VERSION ""

NS_ :

BS_:

BU_: SME EDME REME KLE GWS RDME

BO_ 3221225472 VECTOR__INDEPENDENT_SIG_MSG: 0 Vector__XXX
 SG_ FC_Contactor_Test : 0|1@0+ (1,0) [0|1] "" Vector__XXX
 SG_ Displayed_SOC : 0|8@1+ (0.5,0) [0|100] "%" Vector__XXX
 SG_ CV_Setpoint : 0|12@1+ (0.1,0) [0|409.4] "Volts" Vector__XXX
 SG_ New_Signal_79 : 16|8@1+ (1,0) [0|0] "" Vector__XXX
 SG_ Frame0_1D6 : 0|8@1+ (1,0) [0|0] "" Vector__XXX
 SG_ Frame1_1D6 : 8|8@1+ (1,0) [0|0] "" Vector__XXX
 SG_ DataHighVol : 0|8@1+ (1,0) [0|0] "" Vector__XXX
 SG_ I_Available : 24|16@1+ (0.1,0) [-500|500] "Amps" Vector__XXX
 SG_ V_Avail : 8|16@1+ (0.1,0) [0|1000] "Volts" Vector__XXX
 SG_ Thresh_V : 40|16@1+ (0.1,0) [0|600] "V" Vector__XXX
 SG_ Weld_Det_En : 0|2@1+ (1,0) [0|4] "" Vector__XXX
 SG_ internal_charger_status : 2|4@1+ (1,0) [0|16] "" Vector__XXX
 SG_ CCS_Protocol : 56|8@1+ (1,0) [0|255] "" Vector__XXX
 SG_ Iso_Status : 6|2@1+ (1,0) [0|3] "" Vector__XXX
 SG_ MinV_Avail : 0|16@1+ (0.1,0) [0|1000] "Volts" Vector__XXX
 SG_ Min_I_Avail : 16|12@1+ (0.1,0) [0|410] "A" Vector__XXX
 SG_ Energy_Transmitted : 56|8@1+ (0.25,0) [0|63] "kWh" Vector__XXX
 SG_ Power_Limit : 52|2@1+ (1,0) [0|2] "" Vector__XXX
 SG_ Battery_Compatability : 38|2@1+ (1,0) [0|4] "" Vector__XXX
 SG_ CHG_Volts : 0|16@1+ (0.1,0) [0|1] "Volts" Vector__XXX
 SG_ CHG_Amps : 16|16@1+ (0.1,0) [-500|500] "Amps" Vector__XXX
 SG_ I_Limit : 44|2@1+ (1,0) [0|1] "" Vector__XXX
 SG_ V_Limit : 46|2@1+ (1,0) [0|3] "" Vector__XXX
 SG_ Batt_Malf : 40|2@1+ (1,0) [0|3] "" Vector__XXX
 SG_ Charge_Status : 32|2@1+ (1,0) [0|3] "" Vector__XXX
 SG_ CCS_Malf : 34|2@1+ (1,0) [0|3] "" Vector__XXX
 SG_ DC_Chg_Stop : 42|2@1+ (1,0) [0|3] "" Vector__XXX
 SG_ Pilot_Current : 0|8@1+ (1,0) [0|63] "Amps" Vector__XXX
 SG_ Cable_Current : 8|8@1+ (1,0) [0|63] "Amps" Vector__XXX
 SG_ FC_Voltage : 56|8@1+ (2,0) [0|500] "Volts" Vector__XXX
 SG_ Pilot_Status : 32|3@1+ (1,0) [0|1] "" Vector__XXX
 SG_ PP_Status : 23|2@1+ (1,0) [0|1] "" Vector__XXX
 SG_ CP_Lock_Status : 26|2@1+ (1,0) [0|1] "" Vector__XXX
 SG_ CHG_Flap_Status : 24|2@1+ (1,0) [0|4] "" Vector__XXX
 SG_ Plug_Connection : 37|2@1+ (1,0) [0|4] "" Vector__XXX
 SG_ Charge_End_Sig : 20|2@1+ (1,0) [0|4] "" Vector__XXX
 SG_ HW_Charger_EN : 22|2@1+ (1,0) [0|1] "" Vector__XXX
 SG_ CCS_Plug : 35|2@1+ (1,0) [0|1] "" Vector__XXX
 SG_ Charging_Type : 48|8@1+ (1,0) [0|1] "" Vector__XXX
 SG_ DC_Chg_Volts : 39|9@1+ (2,0) [0|1000] "V" Vector__XXX
 SG_ FC_Contactor_Info : 20|4@1+ (1,0) [0|15] "" Vector__XXX
 SG_ FC_Contactor_State : 18|2@1+ (1,0) [0|3] "" Vector__XXX
 SG_ ChargeFlap_Status : 16|2@1+ (1,0) [0|4] "" Vector__XXX
 SG_ Hook_Pos : 0|2@1+ (1,0) [0|3] "" Vector__XXX
 SG_ Hook_Lock : 2|2@1+ (1,0) [0|3] "" Vector__XXX
 SG_ Chg_End : 18|2@1+ (1,0) [0|1] "" Vector__XXX
 SG_ FC_End : 16|2@1+ (1,0) [0|1] "" Vector__XXX
 SG_ Target_CHG_Ph : 20|4@1+ (1,0) [0|1] "" Vector__XXX
 SG_ Time2Go : 0|16@1+ (1,0) [0|65534] "Mins" Vector__XXX
 SG_ Target_Volts : 24|14@1+ (0.1,0) [0|1000] "V" Vector__XXX
 SG_ frame0_1d6 : 0|8@1+ (1,0) [0|0] "" Vector__XXX
 SG_ frame1_1d6 : 8|8@1+ (1,0) [0|0] "" Vector__XXX
 SG_ Frame_0_1EE : 0|8@1+ (1,0) [0|0] "" Vector__XXX
 SG_ Frame_1_1EE : 8|8@1+ (1,0) [0|0] "" Vector__XXX
 SG_ POSITION_1 : 16|16@1+ (0.005,0) [0|1] "" Vector__XXX
 SG_ lock_button : 22|2@1+ (1,0) [0|4] "" Vector__XXX
 SG_ doors : 8|8@1+ (1,0) [0|0] "" Vector__XXX
 SG_ locks : 0|8@1+ (1,0) [0|0] "" Vector__XXX
 SG_ boot : 16|6@1+ (1,0) [0|0] "" Vector__XXX
 SG_ UnusedFF : 24|40@1+ (1,0) [0|0] "" Vector__XXX
 SG_ Time_to_FC_SOC : 40|16@1+ (10,0) [0|655320] "Secs" Vector__XXX
 SG_ Time_to_SOC : 24|16@1+ (10,0) [0|655320] "Secs" Vector__XXX
 SG_ FC_SOC : 56|8@1+ (0.5,0) [0|100] "%" Vector__XXX
 SG_ CHG_I_Lim : 16|8@1+ (1,0) [0|254] "Amps" Vector__XXX
 SG_ CHG_V_Lim : 0|14@1- (0.1,0) [0|1000] "Volts" Vector__XXX
 SG_ BatteryVoltage : 16|12@1+ (1,0) [0|0] "" Vector__XXX

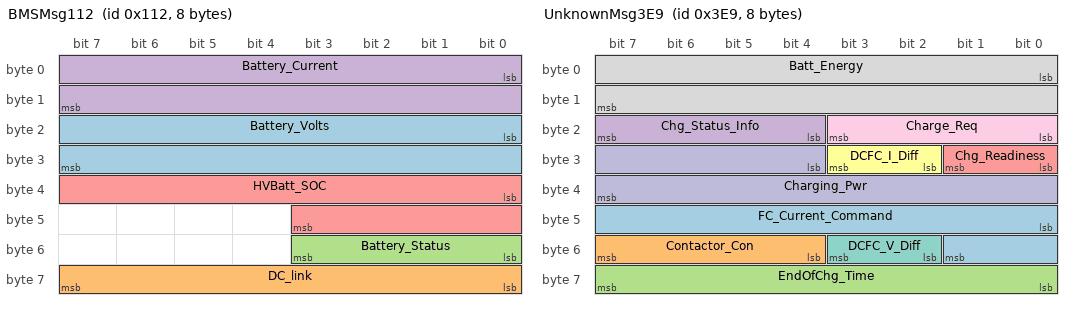
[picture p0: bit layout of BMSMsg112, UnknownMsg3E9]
BO_ 274 BMSMsg112: 8 SME
 SG_ Battery_Volts : 16|16@1+ (0.1,0) [0|500] "Volts" Vector__XXX
 SG_ DC_link : 56|8@1+ (4,0) [0|1000] "Volts" Vector__XXX
 SG_ Battery_Status : 48|4@1+ (1,0) [0|16] "" Vector__XXX
 SG_ Battery_Current : 0|16@1+ (0.1,-819.2) [0|819] "Amps" Vector__XXX
 SG_ HVBatt_SOC : 32|12@1+ (0.1,0) [0|100] "%" Vector__XXX

BO_ 1001 UnknownMsg3E9: 8 EDME
 SG_ FC_Current_Command : 40|10@1- (1,0) [-500|500] "Amps" Vector__XXX
 SG_ Contactor_Con : 52|4@1+ (1,0) [0|16] "" Vector__XXX
 SG_ EndOfChg_Time : 56|8@1+ (1,0) [0|255] "Mins" Vector__XXX
 SG_ Chg_Status_Info : 20|4@1+ (1,0) [0|3] "" Vector__XXX
 SG_ Chg_Readiness : 24|2@1+ (1,0) [0|3] "" Vector__XXX
 SG_ DCFC_I_Diff : 26|2@1+ (1,0) [0|3] "" Vector__XXX
 SG_ DCFC_V_Diff : 50|2@1+ (1,0) [0|3] "" Vector__XXX
 SG_ Batt_Energy : 0|16@1+ (1,0) [0|65534] "Wh" Vector__XXX
 SG_ Charge_Req : 16|4@1+ (1,0) [0|16] "" Vector__XXX
 SG_ Charging_Pwr : 28|12@1+ (25,0) [0|102350] "Watts" Vector__XXX

BO_ 1073 BMSMsg431: 7 SME
 SG_ Serv_Dis_Status : 0|2@1+ (1,0) [0|1] "" Vector__XXX
 SG_ Total_Battery : 40|12@1+ (0.02,0) [0|82] "kWh" Vector__XXX

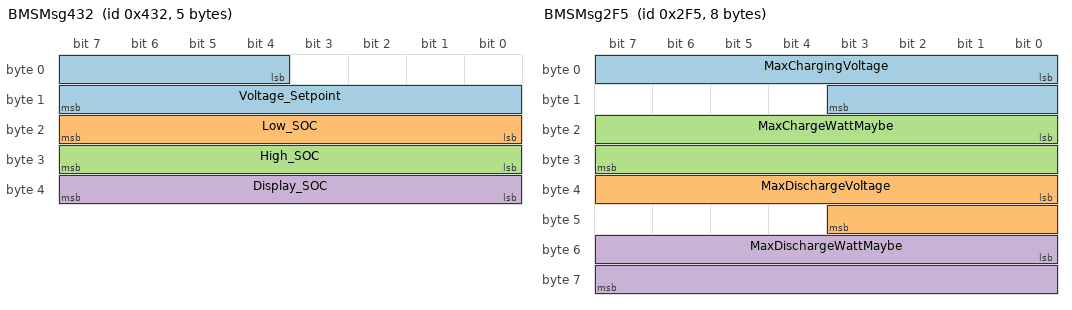
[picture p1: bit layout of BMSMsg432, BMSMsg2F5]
BO_ 1074 BMSMsg432: 5 SME
 SG_ Voltage_Setpoint : 4|12@1+ (0.1,0) [0|410] "Volts" Vector__XXX
 SG_ Low_SOC : 16|8@1+ (0.5,0) [0|100] "%" Vector__XXX
 SG_ High_SOC : 24|8@1+ (0.5,0) [0|100] "%" Vector__XXX
 SG_ Display_SOC : 32|8@1+ (0.5,0) [0|100] "%" Vector__XXX

BO_ 808 UnknownMsg328: 6 EDME
 SG_ Seconds_ctr : 0|32@1+ (1,0) [0|2704] "S" Vector__XXX
 SG_ Day_ctr : 32|16@1+ (1,0) [0|65534] "Days" Vector__XXX

BO_ 303 UnknownMsg12f: 8 EDME
 SG_ ST_KL : 16|4@1+ (1,0) [0|15] "" Vector__XXX

BO_ 1000 UnknownMsg3e8: 2 EDME
 SG_ RQ_Diag : 2|2@1+ (1,0) [0|4] "" Vector__XXX

BO_ 816 OdometerMsg330: 8 EDME
 SG_ Odometer : 0|24@1+ (1,0) [0|16777200] "km" Vector__XXX

BO_ 1072 BMSMsg430: 8 SME
 SG_ UnknownMaybeMaxVoltage : 0|12@1+ (1,0) [0|0] "" Vector__XXX
 SG_ UnknownMaybeMinVoltage : 16|12@1+ (1,0) [0|0] "" Vector__XXX

BO_ 506 BMSMsg1FA: 8 SME

BO_ 1037 BMSMsg40D: 8 SME

BO_ 767 BMSMsg2FF: 6 SME

BO_ 569 BMSMsg239: 8 SME
 SG_ TemperatureMaxMaybe : 16|8@1+ (1,0) [0|0] "" Vector__XXX

BO_ 701 BMSMsg2BD: 8 SME

BO_ 757 BMSMsg2F5: 8 SME
 SG_ MaxChargingVoltage : 0|12@1+ (0.1,0) [0|410] "V+1" Vector__XXX
 SG_ MaxDischargeVoltage : 32|12@1+ (0.1,0) [0|410] "V+1" Vector__XXX
 SG_ MaxChargeWattMaybe : 16|16@1+ (1,0) [0|0] "" Vector__XXX
 SG_ MaxDischargeWattMaybe : 48|16@1+ (1,0) [0|0] "" Vector__XXX

BO_ 962 BMSMsg3C2: 8 SME

BO_ 1003 BMSMsg3EB: 8 SME

BO_ 867 BMSMsg363: 8 SME

BO_ 1287 BMSMsg507: 8 SME

BO_ 1415 BMSMsg587: 8 SME

BO_ 1052 BMSMsg41C: 2 SME
 SG_ Frame0_41C : 0|8@1+ (1,0) [0|0] "" Vector__XXX
 SG_ Frame1_41C : 8|8@1+ (1,0) [0|0] "" Vector__XXX

BO_ 1543 BMSMsg607: 8 SME

BO_ 1017 UnknownMsg3f9: 8 Vector__XXX
 SG_ GEAR : 48|8@1+ (1,0) [0|255] "" Vector__XXX

BO_ 417 UnknownMsg1A1: 5 Vector__XXX

BO_ 896 VINMsg380: 7 EDME
 SG_ VIN : 0|56@1+ (1,0) [0|0] "" Vector__XXX

BO_ 165 UnknownMsg0A5: 8 Vector__XXX

BO_ 704 UnknownMsg2C0: 8 Vector__XXX

BO_ 168 UnknownMsg0A8: 8 Vector__XXX

BO_ 205 UnknownMsg0CD: 8 Vector__XXX

BO_ 667 UnknownMsg29B: 8 Vector__XXX

BO_ 668 UnknownMsg29C: 8 Vector__XXX

BO_ 669 UnknownMsg29D: 8 Vector__XXX

BO_ 407 UnknownMsg197: 4 EDME
 SG_ counter_197 : 8|4@1+ (1,0) [0|14] "" Vector__XXX

BO_ 1290 UnknownMsg50A: 8 Vector__XXX

BO_ 748 UnknownMsg2EC: 2 Vector__XXX

BO_ 1289 UnknownMsg509: 8 Vector__XXX

BO_ 1075 UnknownMsg433: 4 EDME

BO_ 339 UnknownMsg153: 8 Vector__XXX

BO_ 173 UnknownMsg0AD: 8 Vector__XXX

BO_ 187 UnknownMsg0BB: 3 Vector__XXX

BO_ 256 UnknownMsg100: 8 Vector__XXX

BO_ 264 UnknownMsg108: 8 EDME

BO_ 317 UnknownMsg13D: 8 Vector__XXX

BO_ 267 UnknownMsg10B: 3 Vector__XXX

BO_ 318 UnknownMsg13E: 8 Vector__XXX

BO_ 402 UnknownMsg192: 8 Vector__XXX

BO_ 695 UnknownMsg2B7: 8 Vector__XXX

BO_ 738 UnknownMsg2E2: 8 Vector__XXX

BO_ 744 UnknownMsg2E8: 8 Vector__XXX

BO_ 815 UnknownMsg32F: 8 Vector__XXX

BO_ 932 UnknownMsg3A4: 8 Vector__XXX

BO_ 997 UnknownMsg3E5: 3 Vector__XXX

BO_ 1004 UnknownMsg3EC: 8 Vector__XXX

BO_ 1021 UnknownMsg3FD: 5 Vector__XXX

BO_ 1065 UnknownMsg429: 3 Vector__XXX

BO_ 1298 UnknownMsg512: 8 Vector__XXX

BO_ 261 UnknownMsg105: 8 Vector__XXX

BO_ 464 UnknownMsg1D0: 8 Vector__XXX

BO_ 414 UnknownMsg19E: 8 EDME

BO_ 1048 UnknownMsg418: 8 Vector__XXX

BO_ 691 UnknownMsg2B3: 8 Vector__XXX

BO_ 969 UnknownMsg3C9: 8 Vector__XXX

BO_ 1019 UnknownMsg3FB: 6 Vector__XXX

BO_ 1020 UnknownMsg3FC: 3 Vector__XXX

BO_ 170 UnknownMsg0AA: 8 Vector__XXX

BO_ 270 UnknownMsg10E: 8 Vector__XXX

BO_ 336 UnknownMsg150: 8 Vector__XXX

BO_ 426 UnknownMsg1AA: 8 Vector__XXX

BO_ 529 UnknownMsg211: 7 Vector__XXX

BO_ 702 UnknownMsg2BE: 8 Vector__XXX

BO_ 714 UnknownMsg2CA: 2 Vector__XXX

BO_ 739 UnknownMsg2E3: 8 Vector__XXX

BO_ 806 UnknownMsg326: 8 Vector__XXX

BO_ 935 UnknownMsg3A7: 7 Vector__XXX

BO_ 970 UnknownMsg3CA: 8 Vector__XXX

BO_ 976 UnknownMsg3D0: 2 Vector__XXX

BO_ 1053 UnknownMsg41D: 4 Vector__XXX

BO_ 1301 UnknownMsg515: 8 Vector__XXX

BO_ 1306 UnknownMsg51A: 8 Vector__XXX

BO_ 1374 UnknownMsg55E: 8 Vector__XXX

BO_ 1434 UnknownMsg59A: 8 Vector__XXX

CM_ BU_ SME "Battery Management Electronics";
CM_ BU_ EDME "Electrical Digital Motor Electronics";
CM_ BU_ REME "Range Extender Electrical Machine Electronics";
CM_ BU_ KLE "Convenience Charging Electronics";
CM_ BU_ GWS "Electronic Gear Selector Switch";
CM_ BU_ RDME "Range Extender Digital Engine Electronics";
CM_ BO_ 3221225472 "This is a message for not used signals, created by Vector CANdb++ DBC OLE DB Provider.";
CM_ SG_ 3221225472 Frame0_1D6 "0xF0 in logs";
CM_ SG_ 3221225472 Frame1_1D6 "0xC0 in logs";
CM_ SG_ 3221225472 frame0_1d6 "0xF0 in logs
";
CM_ SG_ 3221225472 frame1_1d6 "0xCC -> 0xC0 in logs";
CM_ SG_ 3221225472 Frame_0_1EE "0x00 in logs";
CM_ SG_ 3221225472 Frame_1_1EE "0xFC in logs";
CM_ SG_ 3221225472 POSITION_1 "Steering angle";
CM_ SG_ 3221225472 UnusedFF "Always 0xFF";
CM_ BO_ 274 "10ms - Status Of High-Voltage Battery 2";
CM_ BO_ 1001 "200ms - Main control for LIM
";
CM_ BO_ 1073 "200ms - Data High-Voltage Battery Unit";
CM_ BO_ 1074 "200ms - Battery SOC info";
CM_ BO_ 808 "1000ms - Counter (Relayed from KOMBI)";
CM_ BO_ 303 "100ms - Wake up message (Relayed from BDC)";
CM_ BO_ 1000 "1000ms";
CM_ BO_ 816 "200ms - Range info";
CM_ BO_ 1072 "1s (Non periodic)";
CM_ SG_ 1072 UnknownMaybeMaxVoltage "3943 in 60AH log (394,3V?) Dala guessing";
CM_ SG_ 1072 UnknownMaybeMinVoltage "3383 in 60Ah log (338,3V) Dala guessing";
CM_ BO_ 506 "1s - Status Of High-Voltage Battery 1";
CM_ BO_ 1037 "1s";
CM_ BO_ 767 "100ms";
CM_ BO_ 569 "200ms - Data high voltage battery Unit 2";
CM_ SG_ 569 TemperatureMaxMaybe "Temperature might reside here";
CM_ BO_ 701 "100ms";
CM_ BO_ 757 "100ms - High-Voltage BatteryUnit Charge/Discharge Limitation";
CM_ SG_ 757 MaxChargingVoltage "60AH = 3936 , 94AH = 3964
";
CM_ SG_ 757 MaxDischargeVoltage "60AH = 2594 , 94AH = 2607";
CM_ SG_ 757 MaxChargeWattMaybe "99% 60AH 8280 , 48% 94AH 12072";
CM_ SG_ 757 MaxDischargeWattMaybe "99% 60AH 4102 , 48% 94AH 4429";
CM_ BO_ 962 "1s - 94AH (not on 60AH)";
CM_ BO_ 1003 "1s";
CM_ BO_ 867 "1s";
CM_ BO_ 1287 "Stops after 5 messages sent (640ms)";
CM_ BO_ 1415 "5s";
CM_ BO_ 1052 "1s - Status Of Operating Mode Of Hybrid 2";
CM_ SG_ 1052 Frame0_41C "Static 0xFF";
CM_ SG_ 1052 Frame1_41C "Static 0xFC";
CM_ BO_ 1543 "100ms (Non periodic)";
CM_ BO_ 1017 "1s - Drivetrain gear selector (Also on K-CAN)";
CM_ BO_ 417 "20ms - Vehicle speed";
CM_ BO_ 896 "Stops after 3 messages on startup - VIN";
CM_ BO_ 165 "10ms ";
CM_ BO_ 704 "100ms";
CM_ BO_ 168 "10ms";
CM_ BO_ 205 "10ms";
CM_ BO_ 667 "100ms";
CM_ BO_ 668 "100ms";
CM_ BO_ 669 "100ms";
CM_ BO_ 407 "30ms - Status gear selector switch (Relayed from GWS on i8)";
CM_ SG_ 407 counter_197 "0-E increments each message";
CM_ BO_ 1290 "650ms";
CM_ BO_ 748 "2s";
CM_ BO_ 1289 "Stops after 5 messages sent (640ms)";
CM_ BO_ 1075 "1s - Predefine high-voltage battery (Relayed from EME on i8)";
CM_ BO_ 339 "20ms";
CM_ BO_ 173 "10ms ";
CM_ BO_ 187 "10ms ";
CM_ BO_ 256 "10ms";
CM_ BO_ 264 "100ms - Actual Charging Electronics Data (Relayed from EME)";
CM_ BO_ 317 "10ms ";
CM_ BO_ 267 "20ms";
CM_ BO_ 318 "1s";
CM_ BO_ 402 "1s";
CM_ BO_ 695 "100ms";
CM_ BO_ 738 "1s (changes rate often)";
CM_ BO_ 744 "100ms";
CM_ BO_ 815 "200ms";
CM_ BO_ 932 "1s (Non periodic)";
CM_ BO_ 997 "10s";
CM_ BO_ 1004 "1s";
CM_ BO_ 1021 "100ms";
CM_ BO_ 1065 "50ms";
CM_ BO_ 1298 "640ms";
CM_ BO_ 261 "10ms ";
CM_ BO_ 464 "1s";
CM_ BO_ 414 "500ms (Relayed from EME)";
CM_ BO_ 1048 "1s";
CM_ BO_ 691 "100ms";
CM_ BO_ 969 "1s (Non periodic)";
CM_ BO_ 1019 "1s";
CM_ BO_ 1020 "5s";
CM_ BO_ 170 "10ms ";
CM_ BO_ 270 "20ms";
CM_ BO_ 336 "10ms";
CM_ BO_ 426 "50ms";
CM_ BO_ 529 "100ms";
CM_ BO_ 702 "100ms";
CM_ BO_ 714 "1s - On F10/F11 BMW this is (outside air temperature (Relayed from KOMBI))";
CM_ BO_ 739 "100ms";
CM_ BO_ 806 "500ms";
CM_ BO_ 935 "1s";
CM_ BO_ 970 "1s";
CM_ BO_ 976 "1s";
CM_ BO_ 1053 "1s";
CM_ BO_ 1301 "Stops after 5 messages sent (640ms)";
CM_ BO_ 1306 "640ms";
CM_ BO_ 1374 "Stops after 5 messages sent (640ms)";
CM_ BO_ 1434 "100ms (Non periodic)";
VAL_ 274 Battery_Status 5 "Normal" ;
VAL_ 1001 Contactor_Con 0 "Open" 1 "OpenwithDiag" 2 "Close" 21 "Invalid" ;
VAL_ 1001 Chg_Status_Info 0 "No_charge" 1 "Init" 2 "Charge_active" 3 "Charge_pause" 4 "Charge_complete" 5 "Charge_error" 15 "Invalid" ;
VAL_ 1001 Chg_Readiness 0 "Not_Ready" 1 "Ready" 3 "Unavailable" ;
VAL_ 1001 Charge_Req 0 "No_Charge" 1 "PlugCharge" 2 "Timer" ;
VAL_ 303 ST_KL 0 "No Description" ;
VAL_ 1000 RQ_Diag 0 "No_Reset" 2 "Reset" ;
